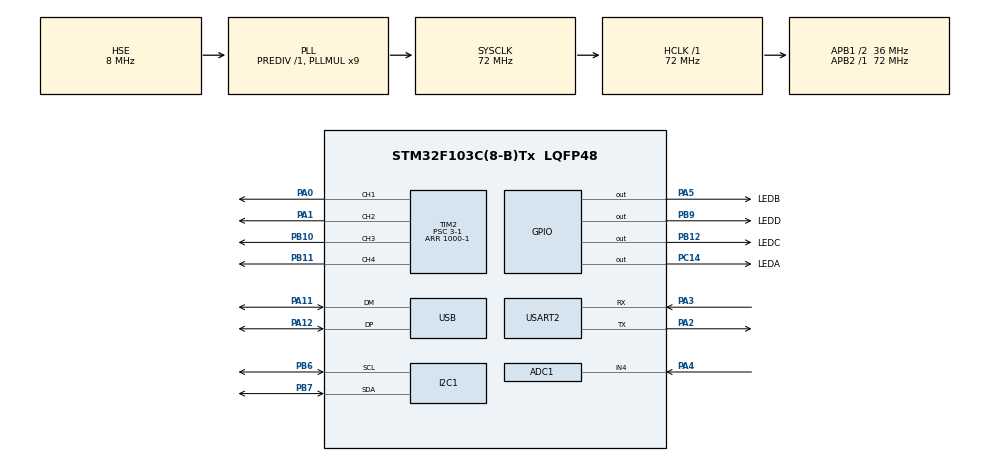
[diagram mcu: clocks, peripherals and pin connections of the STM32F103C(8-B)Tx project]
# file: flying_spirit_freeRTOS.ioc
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ADC1.AutoInjectedConv=DISABLE
ADC1.Channel-33\#ChannelRegularConversion=ADC_CHANNEL_4
ADC1.ContinuousConvMode=ENABLE
ADC1.DataAlign=ADC_DATAALIGN_RIGHT
ADC1.DiscontinuousConvMode=DISABLE
ADC1.EnableAnalogWatchDog=false
ADC1.EnableRegularConversion=ENABLE
ADC1.ExternalTrigConv=ADC_SOFTWARE_START
ADC1.InjNumberOfConversion=0
ADC1.InjectedDiscontinuousConvMode=DISABLE
ADC1.NbrOfConversion=1
ADC1.NbrOfConversionFlag=1
ADC1.Rank-33\#ChannelRegularConversion=1
ADC1.SamplingTime-33\#ChannelRegularConversion=ADC_SAMPLETIME_55CYCLES_5
ADC1.ScanConvMode=ADC_SCAN_DISABLE
ADC1.master=1
Dma.ADC1.0.Direction=DMA_PERIPH_TO_MEMORY
Dma.ADC1.0.Instance=DMA1_Channel1
Dma.ADC1.0.MemDataAlignment=DMA_MDATAALIGN_HALFWORD
Dma.ADC1.0.MemInc=DMA_MINC_ENABLE
Dma.ADC1.0.Mode=DMA_CIRCULAR
Dma.ADC1.0.PeriphDataAlignment=DMA_PDATAALIGN_HALFWORD
Dma.ADC1.0.PeriphInc=DMA_PINC_DISABLE
Dma.ADC1.0.Priority=DMA_PRIORITY_LOW
Dma.Request0=ADC1
FREERTOS.INCLUDE_xTaskAbortDelay=0
FREERTOS.INCLUDE_xTaskGetHandle=0
FREERTOS.MEMORY_ALLOCATION=0
FREERTOS.Tasks01=mainTask,2,128,StartMainTask,Default,NULL,Dynamic,NULL,NULL
FREERTOS.configUSE_DAEMON_TASK_STARTUP_HOOK=0
I2C1.DutyCycle=I2C_DUTYCYCLE_2
Mcu.Family=STM32F1
Mcu.Name=STM32F103C(8-B)Tx
Mcu.Package=LQFP48
NVIC.DMA1_Channel1_IRQn=true\:5\:0\:false\:false\:true\:true
NVIC.PriorityGroup=NVIC_PRIORITYGROUP_4
NVIC.TIM3_IRQn=true\:5\:0\:false\:false\:true\:true
NVIC.TIM4_IRQn=true\:0\:0\:false\:false\:true\:false
NVIC.TimeBase=TIM4_IRQn
NVIC.TimeBaseIP=TIM4
NVIC.USB_LP_CAN1_RX0_IRQn=true\:5\:0\:false\:false\:true\:true
PA0-WKUP.Signal=S_TIM2_CH1_ETR
PA1.Signal=S_TIM2_CH2
PA11.Mode=Device
PA11.Signal=USB_DM
PA12.Mode=Device
PA12.Signal=USB_DP
PA13.Mode=Serial_Wire
PA13.Signal=SYS_JTMS-SWDIO
PA14.Mode=Serial_Wire
PA14.Signal=SYS_JTCK-SWCLK
PA2.Mode=Asynchronous
PA2.Signal=USART2_TX
PA3.Mode=Asynchronous
PA3.Signal=USART2_RX
PA4.Signal=ADCx_IN4
PA5.GPIO_Label=LEDB
PA5.Signal=GPIO_Output
PB10.Signal=S_TIM2_CH3
PB11.Signal=S_TIM2_CH4
PB12.GPIO_Label=LEDC
PB12.Signal=GPIO_Output
PB6.Mode=I2C
PB6.Signal=I2C1_SCL
PB7.Mode=I2C
PB7.Signal=I2C1_SDA
PB9.GPIO_Label=LEDD
PB9.Signal=GPIO_Output
PC14-OSC32_IN.GPIO_Label=LEDA
PC14-OSC32_IN.Signal=GPIO_Output
PD0-OSC_IN.Mode=HSE-External-Oscillator
PD0-OSC_IN.Signal=RCC_OSC_IN
PD1-OSC_OUT.Mode=HSE-External-Oscillator
PD1-OSC_OUT.Signal=RCC_OSC_OUT
ProjectManager.HeapSize=0x1000
ProjectManager.StackSize=0x400
ProjectManager.TargetToolchain=MDK-ARM V5
RCC.ADCPresc=RCC_ADCPCLK2_DIV6
RCC.AHBCLKDivider=RCC_SYSCLK_DIV1
RCC.AHBFreq_Value=72000000
RCC.APB1CLKDivider=RCC_HCLK_DIV2
RCC.APB1Freq_Value=36000000
RCC.APB1TimFreq_Value=72000000
RCC.APB2CLKDivider=RCC_HCLK_DIV1
RCC.APB2Freq_Value=72000000
RCC.APB2TimFreq_Value=72000000
RCC.ClockTypeHCLK=RCC_CLOCKTYPE_HCLK
RCC.ClockTypePCLK1=RCC_CLOCKTYPE_PCLK1
RCC.ClockTypePCLK2=RCC_CLOCKTYPE_PCLK2
RCC.EnableHSE=true
RCC.EnableHSERTCDevisor=false
RCC.EnableLSE=false
RCC.EnableLSERTC=false
RCC.EnableMCOMultDivisor=false
RCC.HCLKFreq_Value=72000000
RCC.HSEState=RCC_HSE_ON
RCC.HSIState=RCC_HSI_ON
RCC.IWDGEnable=false
RCC.LSIState=RCC_LSI_OFF
RCC.MCOEnable=false
RCC.OscillatorTypeHSE=RCC_OSCILLATORTYPE_HSE
RCC.OscillatorTypeHSI=RCC_OSCILLATORTYPE_HSI
RCC.PLLMUL=RCC_PLL_MUL9
RCC.PLLSource=RCC_PLLSOURCE_HSE
RCC.PLLSourceVirtual=RCC_PLLSOURCE_HSE
RCC.PLLState=RCC_PLL_ON
RCC.RTCEnable=false
RCC.SYSCLKFreq_VALUE=72000000
RCC.SYSCLKSource=RCC_SYSCLKSOURCE_PLLCLK
RCC.TimSys_Div=SYSTICK_CLKSOURCE_HCLK
RCC.USBFreq_Value=48000000
RCC.USBPrescaler=RCC_USBCLKSOURCE_PLL_DIV1_5
SH.ADCx_IN4.0=ADC1_IN4,IN4
SH.S_TIM2_CH1_ETR.0=TIM2_CH1,PWM Generation1 CH1
SH.S_TIM2_CH2.0=TIM2_CH2,PWM Generation2 CH2
SH.S_TIM2_CH3.0=TIM2_CH3,PWM Generation3 CH3
SH.S_TIM2_CH4.0=TIM2_CH4,PWM Generation4 CH4
TIM2.Channel-PWM\ Generation1\ CH1=TIM_CHANNEL_1
TIM2.Channel-PWM\ Generation2\ CH2=TIM_CHANNEL_2
TIM2.Channel-PWM\ Generation3\ CH3=TIM_CHANNEL_3
TIM2.Channel-PWM\ Generation4\ CH4=TIM_CHANNEL_4
TIM2.Period=1000-1
TIM2.Prescaler=3-1
TIM3.Period=1000-1
TIM3.Prescaler=72-1
USART2.HwFlowCtl-Asynchronous=UART_HWCONTROL_NONE
USART2.VirtualMode=VM_ASYNC
USB_DEVICE.CLASS_NAME_FS=CDC
USB_DEVICE.USBD_HandleTypeDef_FS=hUsbDevice_USB_FS
USB_DEVICE.VirtualMode=Cdc
USB_DEVICE.VirtualModeFS=Cdc_FS
VP_FREERTOS_VS_ENABLE.Mode=Enabled
VP_SYS_VS_tim4.Mode=TIM4
VP_TIM3_VS_ClockSourceINT.Mode=Internal
VP_USB_DEVICE_VS_USB_DEVICE_CDC_FS.Mode=CDC_FS
board=flying_spirit_freeRTOS

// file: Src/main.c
/**
  ******************************************************************************
  * File Name          : main.c
  * Description        : Main program body
  ******************************************************************************
  *
  * Copyright (c) 2017 STMicroelectronics International N.V.
  * All rights reserved.
  *
  * Redistribution and use in source and binary forms, with or without
  * modification, are permitted, provided that the following conditions are met:
  *
  * 1. Redistribution of source code must retain the above copyright notice,
  *    this list of conditions and the following disclaimer.
  * 2. Redistributions in binary form must reproduce the above copyright notice,
  *    this list of conditions and the following disclaimer in the documentation
  *    and/or other materials provided with the distribution.
  * 3. Neither the name of STMicroelectronics nor the names of other
  *    contributors to this software may be used to endorse or promote products
  *    derived from this software without specific written permission.
  * 4. This software, including modifications and/or derivative works of this
  *    software, must execute solely and exclusively on microcontroller or
  *    microprocessor devices manufactured by or for STMicroelectronics.
  * 5. Redistribution and use of this software other than as permitted under
  *    this license is void and will automatically terminate your rights under
  *    this license.
  *
  * THIS SOFTWARE IS PROVIDED BY STMICROELECTRONICS AND CONTRIBUTORS "AS IS"
  * AND ANY EXPRESS, IMPLIED OR STATUTORY WARRANTIES, INCLUDING, BUT NOT
  * LIMITED TO, THE IMPLIED WARRANTIES OF MERCHANTABILITY, FITNESS FOR A
  * PARTICULAR PURPOSE AND NON-INFRINGEMENT OF THIRD PARTY INTELLECTUAL PROPERTY
  * RIGHTS ARE DISCLAIMED TO THE FULLEST EXTENT PERMITTED BY LAW. IN NO EVENT
  * SHALL STMICROELECTRONICS OR CONTRIBUTORS BE LIABLE FOR ANY DIRECT, INDIRECT,
  * INCIDENTAL, SPECIAL, EXEMPLARY, OR CONSEQUENTIAL DAMAGES (INCLUDING, BUT NOT
  * LIMITED TO, PROCUREMENT OF SUBSTITUTE GOODS OR SERVICES; LOSS OF USE, DATA,
  * OR PROFITS; OR BUSINESS INTERRUPTION) HOWEVER CAUSED AND ON ANY THEORY OF
  * LIABILITY, WHETHER IN CONTRACT, STRICT LIABILITY, OR TORT (INCLUDING
  * NEGLIGENCE OR OTHERWISE) ARISING IN ANY WAY OUT OF THE USE OF THIS SOFTWARE,
  * EVEN IF ADVISED OF THE POSSIBILITY OF SUCH DAMAGE.
  *
  ******************************************************************************
  */
#include "main.h"
#include "stm32f1xx_hal.h"
#include "cmsis_os.h"
#include "adc.h"
#include "dma.h"
#include "i2c.h"
#include "tim.h"
#include "usart.h"
#include "usb_device.h"
#include "gpio.h"

/* USER CODE BEGIN PV */
/* Private variables ---------------------------------------------------------*/

/* USER CODE END PV */

void SystemClock_Config(void);
void Error_Handler(void);
void MX_FREERTOS_Init(void);

/* USER CODE BEGIN PFP */
/* Private function prototypes -----------------------------------------------*/

/* USER CODE END PFP */

int main(void)
{

  /* MCU Configuration----------------------------------------------------------*/

  /* Reset of all peripherals, Initializes the Flash interface and the Systick. */
  HAL_Init();

  /* Configure the system clock */
  SystemClock_Config();

  /* Initialize all configured peripherals */
  MX_GPIO_Init();
  MX_DMA_Init();
  MX_I2C1_Init();
  MX_USART2_UART_Init();
  MX_TIM2_Init();
  MX_ADC1_Init();
  MX_TIM3_Init();

  /* USER CODE BEGIN 2 */
  HAL_ADCEx_Calibration_Start(&hadc1);
  /* USER CODE END 2 */

  /* Call init function for freertos objects (in freertos.c) */
  MX_FREERTOS_Init();

  /* Start scheduler */
  osKernelStart();

  /* We should never get here as control is now taken by the scheduler */

  /* Infinite loop */
  while (1)
  {

  }

}

/** System Clock Configuration
*/
void SystemClock_Config(void)
{

  RCC_OscInitTypeDef RCC_OscInitStruct;
  RCC_ClkInitTypeDef RCC_ClkInitStruct;
  RCC_PeriphCLKInitTypeDef PeriphClkInit;

    /**Initializes the CPU, AHB and APB busses clocks
    */
  RCC_OscInitStruct.OscillatorType = RCC_OSCILLATORTYPE_HSI|RCC_OSCILLATORTYPE_HSE;
  RCC_OscInitStruct.HSEState = RCC_HSE_ON;
  RCC_OscInitStruct.HSEPredivValue = RCC_HSE_PREDIV_DIV1;
  RCC_OscInitStruct.PLL.PLLState = RCC_PLL_ON;
  RCC_OscInitStruct.PLL.PLLSource = RCC_PLLSOURCE_HSE;
  RCC_OscInitStruct.PLL.PLLMUL = RCC_PLL_MUL9;
  if (HAL_RCC_OscConfig(&RCC_OscInitStruct) != HAL_OK)
  {
    Error_Handler();
  }

    /**Initializes the CPU, AHB and APB busses clocks
    */
  RCC_ClkInitStruct.ClockType = RCC_CLOCKTYPE_HCLK|RCC_CLOCKTYPE_SYSCLK
                              |RCC_CLOCKTYPE_PCLK1|RCC_CLOCKTYPE_PCLK2;
  RCC_ClkInitStruct.SYSCLKSource = RCC_SYSCLKSOURCE_PLLCLK;
  RCC_ClkInitStruct.AHBCLKDivider = RCC_SYSCLK_DIV1;
  RCC_ClkInitStruct.APB1CLKDivider = RCC_HCLK_DIV2;
  RCC_ClkInitStruct.APB2CLKDivider = RCC_HCLK_DIV1;

  if (HAL_RCC_ClockConfig(&RCC_ClkInitStruct, FLASH_LATENCY_2) != HAL_OK)
  {
    Error_Handler();
  }

  PeriphClkInit.PeriphClockSelection = RCC_PERIPHCLK_ADC|RCC_PERIPHCLK_USB;
  PeriphClkInit.AdcClockSelection = RCC_ADCPCLK2_DIV6;
  PeriphClkInit.UsbClockSelection = RCC_USBCLKSOURCE_PLL_DIV1_5;
  if (HAL_RCCEx_PeriphCLKConfig(&PeriphClkInit) != HAL_OK)
  {
    Error_Handler();
  }

    /**Configure the Systick interrupt time
    */
  HAL_SYSTICK_Config(HAL_RCC_GetHCLKFreq()/1000);

    /**Configure the Systick
    */
  HAL_SYSTICK_CLKSourceConfig(SYSTICK_CLKSOURCE_HCLK);

  /* SysTick_IRQn interrupt configuration */
  HAL_NVIC_SetPriority(SysTick_IRQn, 15, 0);
}

void HAL_TIM_PeriodElapsedCallback(TIM_HandleTypeDef *htim)
{
  if (htim->Instance == TIM4) {
    HAL_IncTick();
  }
}

void Error_Handler(void)
{
  while(1)
  {
  }
}

/************************ (C) COPYRIGHT STMicroelectronics *****END OF FILE****/

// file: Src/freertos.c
/**
  ******************************************************************************
  * File Name          : freertos.c
  * Description        : Code for freertos applications
  ******************************************************************************
  *
  * Copyright (c) 2017 STMicroelectronics International N.V.
  * All rights reserved.
  *
  * Redistribution and use in source and binary forms, with or without
  * modification, are permitted, provided that the following conditions are met:
  *
  * 1. Redistribution of source code must retain the above copyright notice,
  *    this list of conditions and the following disclaimer.
  * 2. Redistributions in binary form must reproduce the above copyright notice,
  *    this list of conditions and the following disclaimer in the documentation
  *    and/or other materials provided with the distribution.
  * 3. Neither the name of STMicroelectronics nor the names of other
  *    contributors to this software may be used to endorse or promote products
  *    derived from this software without specific written permission.
  * 4. This software, including modifications and/or derivative works of this
  *    software, must execute solely and exclusively on microcontroller or
  *    microprocessor devices manufactured by or for STMicroelectronics.
  * 5. Redistribution and use of this software other than as permitted under
  *    this license is void and will automatically terminate your rights under
  *    this license.
  *
  * THIS SOFTWARE IS PROVIDED BY STMICROELECTRONICS AND CONTRIBUTORS "AS IS"
  * AND ANY EXPRESS, IMPLIED OR STATUTORY WARRANTIES, INCLUDING, BUT NOT
  * LIMITED TO, THE IMPLIED WARRANTIES OF MERCHANTABILITY, FITNESS FOR A
  * PARTICULAR PURPOSE AND NON-INFRINGEMENT OF THIRD PARTY INTELLECTUAL PROPERTY
  * RIGHTS ARE DISCLAIMED TO THE FULLEST EXTENT PERMITTED BY LAW. IN NO EVENT
  * SHALL STMICROELECTRONICS OR CONTRIBUTORS BE LIABLE FOR ANY DIRECT, INDIRECT,
  * INCIDENTAL, SPECIAL, EXEMPLARY, OR CONSEQUENTIAL DAMAGES (INCLUDING, BUT NOT
  * LIMITED TO, PROCUREMENT OF SUBSTITUTE GOODS OR SERVICES; LOSS OF USE, DATA,
  * OR PROFITS; OR BUSINESS INTERRUPTION) HOWEVER CAUSED AND ON ANY THEORY OF
  * LIABILITY, WHETHER IN CONTRACT, STRICT LIABILITY, OR TORT (INCLUDING
  * NEGLIGENCE OR OTHERWISE) ARISING IN ANY WAY OUT OF THE USE OF THIS SOFTWARE,
  * EVEN IF ADVISED OF THE POSSIBILITY OF SUCH DAMAGE.
  *
  ******************************************************************************
  */

#include "FreeRTOS.h"
#include "task.h"
#include "cmsis_os.h"
#include "mpu6050.h"
#include "usbd_cdc_if.h"

osThreadId mainTaskHandle;

void StartMainTask(void const * argument);

extern void MX_USB_DEVICE_Init(void);
void MX_FREERTOS_Init(void); /* (MISRA C 2004 rule 8.1) */

/* Hook prototypes */

/* Init FreeRTOS */

void MX_FREERTOS_Init(void) {

  /* Create the thread(s) */
  /* definition and creation of mainTask */
  osThreadDef(mainTask, StartMainTask, osPriorityHigh, 0, 128);
  mainTaskHandle = osThreadCreate(osThread(mainTask), NULL);

}

/* StartMainTask function */
void StartMainTask(void const * argument)
{
  /* init code for USB_DEVICE */
  MX_USB_DEVICE_Init();

  /* USER CODE BEGIN StartMainTask */
	MPU6050_Init();
	uint8_t SendData[10];
  /* Infinite loop */
  for(;;)
  {
		Read_MPU6050();
		CDC_Transmit_FS(SendData,10);
    osDelay(1);
  }
  /* USER CODE END StartMainTask */
}

/************************ (C) COPYRIGHT STMicroelectronics *****END OF FILE****/
